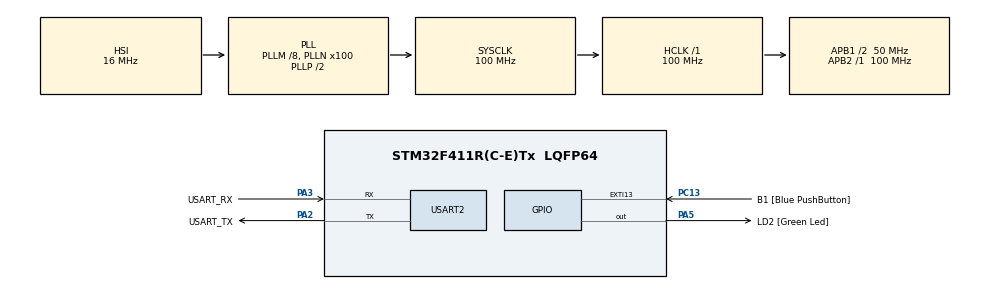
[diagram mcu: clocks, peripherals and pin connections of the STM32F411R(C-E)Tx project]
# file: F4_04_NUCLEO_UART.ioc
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Dma.Request0=USART2_TX
Dma.Request1=USART2_RX
Dma.USART2_RX.1.Direction=DMA_PERIPH_TO_MEMORY
Dma.USART2_RX.1.FIFOMode=DMA_FIFOMODE_DISABLE
Dma.USART2_RX.1.Instance=DMA1_Stream5
Dma.USART2_RX.1.MemDataAlignment=DMA_MDATAALIGN_BYTE
Dma.USART2_RX.1.MemInc=DMA_MINC_ENABLE
Dma.USART2_RX.1.Mode=DMA_NORMAL
Dma.USART2_RX.1.PeriphDataAlignment=DMA_PDATAALIGN_BYTE
Dma.USART2_RX.1.PeriphInc=DMA_PINC_DISABLE
Dma.USART2_RX.1.Priority=DMA_PRIORITY_LOW
Dma.USART2_TX.0.Direction=DMA_MEMORY_TO_PERIPH
Dma.USART2_TX.0.FIFOMode=DMA_FIFOMODE_DISABLE
Dma.USART2_TX.0.Instance=DMA1_Stream6
Dma.USART2_TX.0.MemDataAlignment=DMA_MDATAALIGN_BYTE
Dma.USART2_TX.0.MemInc=DMA_MINC_ENABLE
Dma.USART2_TX.0.Mode=DMA_NORMAL
Dma.USART2_TX.0.PeriphDataAlignment=DMA_PDATAALIGN_BYTE
Dma.USART2_TX.0.PeriphInc=DMA_PINC_DISABLE
Dma.USART2_TX.0.Priority=DMA_PRIORITY_LOW
Mcu.Family=STM32F4
Mcu.Name=STM32F411R(C-E)Tx
Mcu.Package=LQFP64
NVIC.DMA1_Stream5_IRQn=true\:0\:0\:false\:false\:true\:false\:true\:true
NVIC.DMA1_Stream6_IRQn=true\:0\:0\:false\:false\:true\:false\:true\:true
NVIC.PriorityGroup=NVIC_PRIORITYGROUP_0
NVIC.TIM1_UP_TIM10_IRQn=true\:0\:0\:false\:false\:true\:true\:true\:true
NVIC.USART2_IRQn=true\:0\:0\:false\:false\:true\:true\:true\:true
PA13.GPIO_Label=TMS
PA13.Mode=Serial_Wire
PA13.Signal=SYS_JTMS-SWDIO
PA14.GPIO_Label=TCK
PA14.Mode=Serial_Wire
PA14.Signal=SYS_JTCK-SWCLK
PA2.GPIO_Label=USART_TX
PA2.Mode=Asynchronous
PA2.Signal=USART2_TX
PA3.GPIO_Label=USART_RX
PA3.Mode=Asynchronous
PA3.Signal=USART2_RX
PA5.GPIO_Label=LD2 [Green Led]
PA5.Signal=GPIO_Output
PB3.GPIO_Label=SWO
PB3.Signal=SYS_JTDO-SWO
PC13-ANTI_TAMP.GPIO_Label=B1 [Blue PushButton]
PC13-ANTI_TAMP.GPIO_ModeDefaultEXTI=GPIO_MODE_IT_FALLING
PC13-ANTI_TAMP.Signal=GPXTI13
PC14-OSC32_IN.Mode=LSE-External-Oscillator
PC14-OSC32_IN.Signal=RCC_OSC32_IN
PC15-OSC32_OUT.Mode=LSE-External-Oscillator
PC15-OSC32_OUT.Signal=RCC_OSC32_OUT
PH0\ -\ OSC_IN.Mode=HSE-External-Clock-Source
PH0\ -\ OSC_IN.Signal=RCC_OSC_IN
PH1\ -\ OSC_OUT.Mode=HSE-External-Clock-Source
PH1\ -\ OSC_OUT.Signal=RCC_OSC_OUT
ProjectManager.HeapSize=0x200
ProjectManager.StackSize=0x400
ProjectManager.TargetToolchain=STM32CubeIDE
RCC.48MHZClocksFreq_Value=50000000
RCC.AHBFreq_Value=100000000
RCC.APB1CLKDivider=RCC_HCLK_DIV2
RCC.APB1Freq_Value=50000000
RCC.APB1TimFreq_Value=100000000
RCC.APB2Freq_Value=100000000
RCC.APB2TimFreq_Value=100000000
RCC.CortexFreq_Value=100000000
RCC.FLatency-AdvancedSettings=FLASH_LATENCY_3
RCC.HCLKFreq_Value=100000000
RCC.HSE_VALUE=8000000
RCC.HSI_VALUE=16000000
RCC.PLLM=8
RCC.PLLN=100
RCC.SYSCLKFreq_VALUE=100000000
RCC.SYSCLKSource=RCC_SYSCLKSOURCE_PLLCLK
RCC.VCOOutputFreq_Value=200000000
TIM10.Period=9999
TIM10.Prescaler=9999
USART2.VirtualMode=VM_ASYNC
VP_TIM10_VS_ClockSourceINT.Mode=Enable_Timer
board=NUCLEO-F411RE

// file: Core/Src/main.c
/* USER CODE BEGIN Header */
/**
  ******************************************************************************
  * @file           : main.c
  * @brief          : Main program body
  ******************************************************************************
  * @attention
  *
  * Copyright (c) 2023 STMicroelectronics.
  * All rights reserved.
  *
  * This software is licensed under terms that can be found in the LICENSE file
  * in the root directory of this software component.
  * If no LICENSE file comes with this software, it is provided AS-IS.
  *
  ******************************************************************************
  */
/* USER CODE END Header */
#include "main.h"
#include "dma.h"
#include "tim.h"
#include "usart.h"
#include "gpio.h"

/* USER CODE BEGIN Includes */
#include <stdio.h>
#include <stdlib.h>
/* USER CODE END Includes */

/* USER CODE BEGIN PV */
//task2
//uint8_t Received;

//task3 & task4
uint8_t Received[10];
/* USER CODE END PV */

void SystemClock_Config(void);
/* USER CODE BEGIN PFP */
void HAL_UART_RxCpltCallback(UART_HandleTypeDef *huart);
void HAL_TIM_PeriodElapsedCallback(TIM_HandleTypeDef *htim);
/* USER CODE END PFP */

int main(void)
{

  /* MCU Configuration--------------------------------------------------------*/

  /* Reset of all peripherals, Initializes the Flash interface and the Systick. */
  HAL_Init();

  /* Configure the system clock */
  SystemClock_Config();

  /* Initialize all configured peripherals */
  MX_GPIO_Init();
  MX_DMA_Init();
  MX_USART2_UART_Init();
  MX_TIM10_Init();
  /* USER CODE BEGIN 2 */
  //task1
  //HAL_TIM_Base_Start_IT(&htim10);

  //task2
  //HAL_UART_Receive_IT(&huart2, &Received, 1);

  //task3
  //HAL_UART_Receive_IT(&huart2, Received, 10);

  // task4 DMA
  HAL_UART_Receive_DMA(&huart2, Received, 10);
  /* USER CODE END 2 */

  /* Infinite loop */
  while (1)
  {

  }
}

void SystemClock_Config(void)
{
  RCC_OscInitTypeDef RCC_OscInitStruct = {0};
  RCC_ClkInitTypeDef RCC_ClkInitStruct = {0};

  /** Configure the main internal regulator output voltage
  */
  __HAL_RCC_PWR_CLK_ENABLE();
  __HAL_PWR_VOLTAGESCALING_CONFIG(PWR_REGULATOR_VOLTAGE_SCALE1);

  /** Initializes the RCC Oscillators according to the specified parameters
  * in the RCC_OscInitTypeDef structure.
  */
  RCC_OscInitStruct.OscillatorType = RCC_OSCILLATORTYPE_HSI;
  RCC_OscInitStruct.HSIState = RCC_HSI_ON;
  RCC_OscInitStruct.HSICalibrationValue = RCC_HSICALIBRATION_DEFAULT;
  RCC_OscInitStruct.PLL.PLLState = RCC_PLL_ON;
  RCC_OscInitStruct.PLL.PLLSource = RCC_PLLSOURCE_HSI;
  RCC_OscInitStruct.PLL.PLLM = 8;
  RCC_OscInitStruct.PLL.PLLN = 100;
  RCC_OscInitStruct.PLL.PLLP = RCC_PLLP_DIV2;
  RCC_OscInitStruct.PLL.PLLQ = 4;
  if (HAL_RCC_OscConfig(&RCC_OscInitStruct) != HAL_OK)
  {
    Error_Handler();
  }

  /** Initializes the CPU, AHB and APB buses clocks
  */
  RCC_ClkInitStruct.ClockType = RCC_CLOCKTYPE_HCLK|RCC_CLOCKTYPE_SYSCLK
                              |RCC_CLOCKTYPE_PCLK1|RCC_CLOCKTYPE_PCLK2;
  RCC_ClkInitStruct.SYSCLKSource = RCC_SYSCLKSOURCE_PLLCLK;
  RCC_ClkInitStruct.AHBCLKDivider = RCC_SYSCLK_DIV1;
  RCC_ClkInitStruct.APB1CLKDivider = RCC_HCLK_DIV2;
  RCC_ClkInitStruct.APB2CLKDivider = RCC_HCLK_DIV1;

  if (HAL_RCC_ClockConfig(&RCC_ClkInitStruct, FLASH_LATENCY_3) != HAL_OK)
  {
    Error_Handler();
  }
}

/* USER CODE BEGIN 4 */

// task1
/*void HAL_TIM_PeriodElapsedCallback(TIM_HandleTypeDef *htim)
{
	if (TIM10 == htim->Instance)
	{
		static uint16_t cnt = 0;
		char data[50];
		uint16_t size = 0;

		cnt++;
		size = sprintf(data, "Liczba wyslanych wiadomosci: %d.\n\r", cnt);
		HAL_UART_Transmit_IT(&huart2, (uint8_t *) data, size);
		HAL_GPIO_TogglePin(LD2_GPIO_Port, LD2_Pin);
	}
}*/

// task2
void HAL_UART_RxCpltCallback(UART_HandleTypeDef *huart)
{
	// task2
	/*uint8_t Data[50];
	uint16_t size = 0;

	switch (atoi( (char *) &Received))
	{
	case 0 :
		size = sprintf((char *) Data, "STOP/n/r");
		HAL_GPIO_WritePin(LD2_GPIO_Port, LD2_Pin, GPIO_PIN_RESET);
		break;

	case 1 :
		size = sprintf((char *) Data, "START\n\r");
		HAL_GPIO_WritePin(LD2_GPIO_Port, LD2_Pin, GPIO_PIN_SET);
		break;

	default:
		size = sprintf((char *) Data, "Odebrano nieznany znak: %c/n/r", Received);
	}

	HAL_UART_Transmit_IT(&huart2, Data, size);
	HAL_UART_Receive_IT(&huart2, &Received, 1);*/

	//task3
	/*uint8_t Data[40];
	//uint16_t size = 0;

	size = sprintf((char *) Data, "Odebrana wiadomosc: %s\n\r", Received);

	//HAL_UART_Transmit_IT(&huart2, Data, size);
	HAL_UART_Transmit_IT(&huart2, Data, sizeof(Data));
	HAL_UART_Receive_IT(&huart2, Received, 10);
	HAL_GPIO_TogglePin(LD2_GPIO_Port, LD2_Pin);*/

	// task4 DMA
	static uint8_t Data[40];

	sprintf((char *) Data, "Odebrana wiadomosc: %s\n\r", Received);

	HAL_UART_Transmit_DMA(&huart2, Data, 40);
	HAL_UART_Receive_DMA(&huart2, Received, 10);
	HAL_GPIO_TogglePin(LD2_GPIO_Port, LD2_Pin);
}
/* USER CODE END 4 */

void Error_Handler(void)
{
  __disable_irq();
  while (1)
  {
  }
}
